# STM32MP13xx register map
File version: 1.5
CPU: CA7 r0p0, little endian, MPU, FPU, 4 interrupt priority bits
Registers are 32-bit, read-write, reset 0x0 unless marked. A register's access mark holds for its fields unless they carry their own. Offsets are from the block's base; [hi:lo] are bit positions; {n}, {i} and the like mark numbered series.

## CRC
Base 0x58009000
0x00 CRC_DR reset 0xFFFFFFFF — CRC data register
  [31:0] DR — Data register bits This register is used to write new data to the CRC calculator. It holds the previous CRC calculation result when it is read. If the data size is less than 32 bits, the least significant bits are used to write/read the correct value.
0x04 CRC_IDR — CRC independent data register
  [31:0] IDR — General-purpose 32-bit data register bits These bits can be used as a temporary storage location for four bytes. This register is not affected by CRC resets generated by the RESET bit in the CRC_CR register
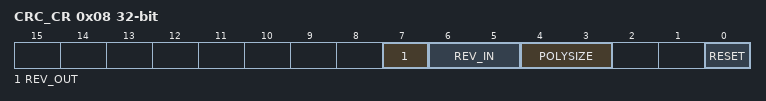
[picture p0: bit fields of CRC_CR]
0x08 CRC_CR — CRC control register
  [7] REV_OUT — Reverse output data This bit controls the reversal of the bit order of the output data.
    0=Bit order not affected; 1=Bit-reversed output format
  [6:5] REV_IN — Reverse input data These bits control the reversal of the bit order of the input data
    0=Bit order not affected; 1=Bit reversal done by byte; 2=Bit reversal done by half-word; 3=Bit reversal done by word
  [4:3] POLYSIZE — Polynomial size These bits control the size of the polynomial.
    0=32 bit polynomial; 1=16 bit polynomial; 2=8 bit polynomial; 3=7 bit polynomial
  [0] RESET — RESET bit This bit is set by software to reset the CRC calculation unit and set the data register to the value stored in the CRC_INIT register. This bit can only be set, it is automatically cleared by hardware
0x10 CRC_INIT reset 0xFFFFFFFF — CRC initial value
  [31:0] CRC_INIT — Programmable initial CRC value This register is used to write the CRC initial value.
0x14 CRC_POL reset 0x4C11DB7 — CRC polynomial
  [31:0] POL — Programmable polynomial This register is used to write the coefficients of the polynomial to be used for CRC calculation. If the polynomial size is less than 32 bits, the least significant bits have to be used to program the correct value.

## DDRPERFM
Base 0x5A007000
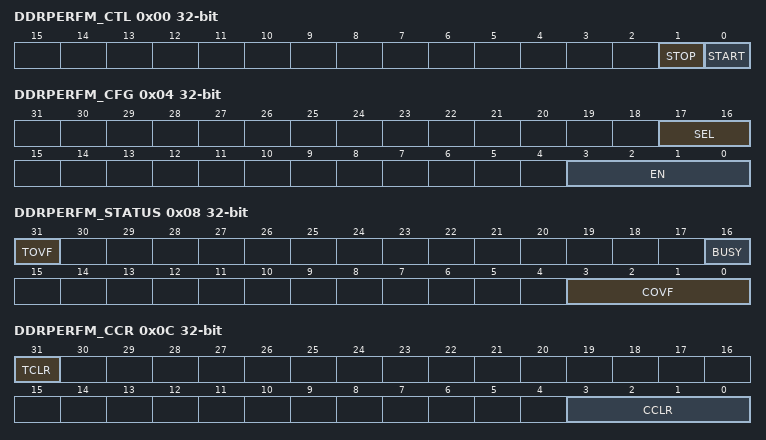
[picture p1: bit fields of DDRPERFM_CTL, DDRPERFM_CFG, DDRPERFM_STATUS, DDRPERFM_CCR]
0x00 DDRPERFM_CTL wo — DDRPERFM control register
  [1] STOP — stop all the counters. Writing a '1â when the counters are stopped (DDRPERFM_STATUS.BUSY = 0) is ignored
    0=writing a '0â has no effect; 1=writing a '1â stops all the counters
  [0] START — Start counters which are enabled, the time counter (TCNT) is always enabled. writing a '1â when the counters are running (DDRPERFM_STATUS.BUSY = 1) is ignored
    0=writing a '0â has no effect; 1=writing a '1â Starts counters which are enabledW
0x04 DDRPERFM_CFG — DDRPERFM configurationl register
  [17:16] SEL — select set of signals to be monitored (from 0 to 3) (see signal set description in ) and counters to be enabled
  [3:0] EN — enable counter x (from 0 to 3)
    0=the corresponding counter is disabled and does not increment; 1=the corresponding counter is enabled and incremented on event at each clock
0x08 DDRPERFM_STATUS ro
  [31] TOVF — total counter overflow
    0=no overflow; 1=counter overflow
  [16] BUSY — Busy Status
    0=DDRPERFM is stopped or a counter is in overflow; 1=DDRPERFM is counting (at least TCNT is counting)
  [3:0] COVF — Counter x Overflow (with x from 0 to 3)
    0=no overflow; 1=counter overflow
0x0C DDRPERFM_CCR wo — DDRPERFM counter clear register
  [31] TCLR — time counter clear
    0=writing a '0â has no effect; 1=writing a '1â clears the time counter
  [3:0] CCLR — counter x Clear (with x from 0 to 3)
    0=writing a '0â has no effect; 1=writing a '1â clears the corresponding event counter x (with x from 0 to 3)
0x10 DDRPERFM_IER — DDRPERFM interrupt enable register
  [0] OVFIE — overflow interrupt enable
    0=overflow interrupt disabled; 1=overflow interrupt enabled
0x14 DDRPERFM_ISR ro — DDRPERFM interrupt status register
  [0] OVFF — overflow flag This flag is set when one counter is in overflow
0x18 DDRPERFM_ICR wo — DDRPERFM interrupt clear register
  [0] OVF — overflow flag
    0=no action; 1=clears the overflow flag
0x20 DDRPERFM_TCNT ro — DDRPERFM time counter register
  [31:0] CNT — total time, this is number of DDR controller clocks elapsed while DDRPERFM has been running.
{0x30+8i} DDRPERFM_CNT{i} ro (i=0..3) — DDRPERFM event counter {i} register
  [31:0] CNT — event counter value.
0x3F0 DDRPERFM_HWCFG ro reset 0x4 — DDRPERFM hardware configuration register
  [3:0] NCNT — number of counters for this configuration (4)
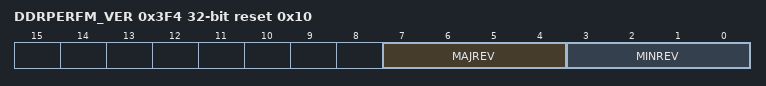
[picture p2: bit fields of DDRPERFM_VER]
0x3F4 DDRPERFM_VER ro reset 0x10 — DDRPERFM version register
  [7:4] MAJREV — Major revision number.
  [3:0] MINREV — Minor revision number.
0x3F8 DDRPERFM_ID ro reset 0x140061
  [31:0] ID — DDRPERFM unique identification.
0x3FC DDRPERFM_SID ro reset 0xA3C5DD01 — DDRPERFM magic ID register
  [31:0] SID — magic ID for automatic IP discovery.
